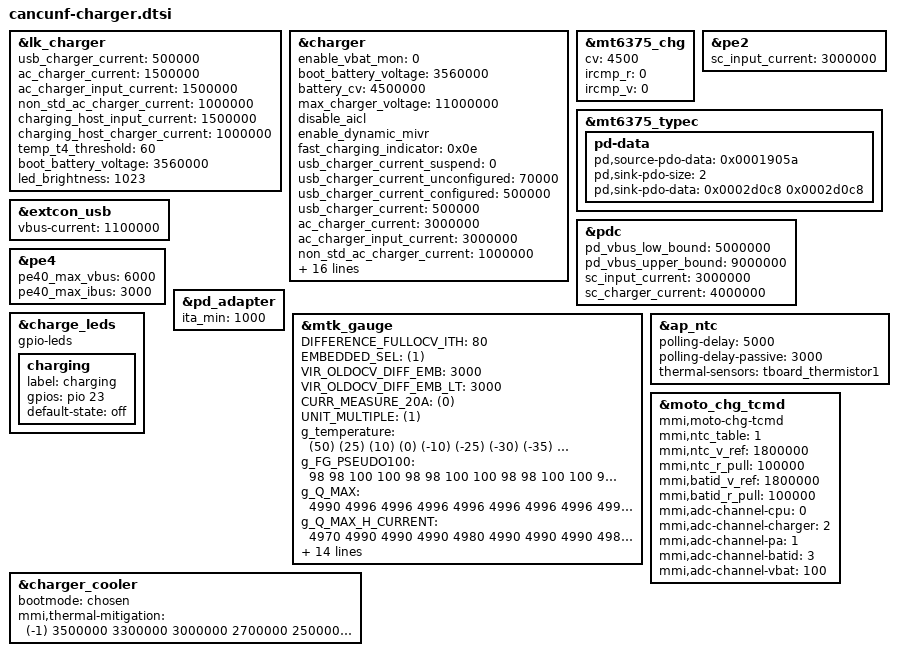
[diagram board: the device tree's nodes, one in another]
/*
 * Copyright (c) 2021 MediaTek Inc.
 *
 * This program is free software; you can redistribute it and/or modify
 * it under the terms of the GNU General Public License version 2 as
 * published by the Free Software Foundation.
 *
 * This program is distributed in the hope that it will be useful,
 * but WITHOUT ANY WARRANTY; without even the implied warranty of
 * MERCHANTABILITY or FITNESS FOR A PARTICULAR PURPOSE.  See the
 * GNU General Public License for more details.
 */

&lk_charger {
	/* charging current */
	usb_charger_current = <500000>;
	ac_charger_current = <1500000>;
	ac_charger_input_current = <1500000>;
	non_std_ac_charger_current = <1000000>;
	charging_host_input_current = <1500000>;
	charging_host_charger_current = <1000000>;

	temp_t4_threshold = <60>;

	boot_battery_voltage = <3560000>;
};

&charger {
	/* sw jeita */
	enable_vbat_mon = <0>;

	/* common */
        boot_battery_voltage = <3560000>;
	battery_cv = <4500000>;
	max_charger_voltage = <11000000>;
//	min_charger_voltage = <4600000>;

        disable_aicl;
        enable_dynamic_mivr;

	/*pdc && pe2*/
	fast_charging_indicator = <0x0e>;
	/*swchg + 1CP*/
	//charger_configuration= <3>;

	/* charging current */
	usb_charger_current_suspend = <0>;
	usb_charger_current_unconfigured = <70000>;
	usb_charger_current_configured = <500000>;
	usb_charger_current = <500000>;
	ac_charger_current = <3000000>;
	ac_charger_input_current = <3000000>;
	non_std_ac_charger_current = <1000000>;
	charging_host_charger_current = <1500000>;
	apple_1_0a_charger_current = <650000>;
	apple_2_1a_charger_current = <800000>;
	ta_ac_charger_current = <2000000>;
	typec_limit_aicr = <3000000>;

	/*mmi config*/
	mmi,iterm-ma = <243>;
	mmi,mmi-temp-zones = <0 4200 1000 0>,
			<10 4500 3000 1000>,
			<15 4500 3000 3000>,
			<45 4500 4000 4000>,
			<60 4200 4000 0>;
	mmi,mmi-ffc-zones = <0 4200 243>,
			<10 4500 243>,
			<15 4500 243>,
			<25 4530 506>,
			<35 4530 560>,
			<45 4530 965>,
			<60 4200 243>;
	mmi,enable-charging-limit;
	mmi,upper-limit-capacity = <65>;
	mmi,lower-limit-capacity = <60>;
	mmi,min-cp-therm-current-ua = <1600000>;
};

&mt6375_chg {
	cv = <4500>;
	ircmp_r = <0>;
	ircmp_v = <0>;
};
/*
&pdc {
	sc_input_current = <3000000>;
};
*/
&pe2 {
	sc_input_current = <3000000>;
};


&mt6375_typec {
	pd-data {
		/* 5V, 900ma */
		pd,source-pdo-data = <0x0001905a>;
		/* 9V, 2A */
		pd,sink-pdo-size = <2>;
                pd,sink-pdo-data = <0x0002d0c8 0x0002d0c8> ;
	};
};

&extcon_usb {
	vbus-current = <1100000>;
};


&pdc {
	pd_vbus_low_bound = <5000000>;
	pd_vbus_upper_bound = <9000000>;

	sc_input_current = <3000000>;
	sc_charger_current = <4000000>;
};



&pe4 {
	pe40_max_vbus = <6000>;
	pe40_max_ibus = <3000>;
};


&pd_adapter{
	ita_min = <1000>;
};

&mtk_gauge {

	DIFFERENCE_FULLOCV_ITH = <80>;  /*gauge cut-off current, should overtop ieoc 50ma*/
	EMBEDDED_SEL = <(1)>;  /*embedded battery,don't remove the battery for user*/
	VIR_OLDOCV_DIFF_EMB = <3000>; /*0.1mv*/
	VIR_OLDOCV_DIFF_EMB_LT = <3000>; /*0.1mv*/
        CURR_MEASURE_20A = <(0)>;
        UNIT_MULTIPLE = <(1)>;

	/* battery prop */
	g_temperature = <(50) (25) (10) (0) (-10) (-25) (-30) (-35) (-40) (-45)>;
	g_FG_PSEUDO100 = <98 98 100 100
		98 98 100 100
		98 98 100 100
		98 98 100 100
		98 98 100 100
		100 100 100 100
		100 100 100 100
		100 100 100 100
		100 100 100 100
		100 100 100 100>;

	g_Q_MAX = <4990 4996 4996 4996
		4996 4996 4996 4996
		4996 4996 4996 4996
		4996 4996 4996 4996
		4990 4996 4996 4996
		4990 4996 4996 4996
		4990 4996 4996 4996
		4990 4996 4996 4996
		4990 4996 4996 4996
		4990 4996 4996 4996>;

	g_Q_MAX_H_CURRENT = <4970 4990 4990 4990
		4980 4990 4990 4990
		4980 4990 4990 4990
		4980 4990 4990 4990
		4970 4990 4990 4990
		4970 4990 4990 4990
		4970 4990 4990 4990
		4970 4990 4990 4990
		4970 4990 4990 4990
		4970 4990 4990 4990>;

	/*vboot voltage for gauge 0%*/
	g_PMIC_MIN_VOL_row = <4>;
	g_PMIC_MIN_VOL_col = <10>;
	g_PMIC_MIN_VOL = <32000  33500  33500  33500
		32000  33500  33000  33000
		33000  33000  33000  33000
		32200  32200  32200  32200
		31360  31360  31360  31360
		31000  31000  31000  31000
		31000  31000  31000  31000
		31000  31000  31000  31000
		31000  31000  31000  31000
		31000  31000  31000  31200>;

	/*Pseudo1 hide percentage*/
	g_QMAX_SYS_VOL_row = <4>;
	g_QMAX_SYS_VOL_col = <10>;
	g_QMAX_SYS_VOL = <32500  34000  34950  34950
		32500  34000  34950  34950
		34250  34250  34250  34250
		34250  34250  34250  34250
		34250  34250  34250  34250
		34250  34250  34250  34250
		32800  32800  32800  32800
		32800  32800  32800  32800
		32800  32800  32800  32800
		32800  32800  32800  32800>;

	SHUTDOWN_1_TIME = <(30)>;
	ACTIVE_TABLE = <(5)>;
	R_FG_VALUE = <(5)>;
	NO_BAT_TEMP_COMPENSATE = <(1)>;
//	df-serialnum = "SB18D61156";
	df-serialnum = "SB18D86478";
	CAR_TUNE_VALUE = <(99)>;
	#include "bat_setting/mt6855_battery_pc50_atl_5000mah.dtsi"
	#include "bat_setting/mt6855_battery_pc50_scud_5000mah.dtsi"
//	#include "bat_setting/mt6855_battery_table_lwn_5000.dtsi"
//	#include "bat_setting/mt6855_battery_table_ff.dtsi"

};

&charge_leds {
	compatible = "gpio-leds";

	charging {
		label = "charging";
		gpios = <&pio 23 0x0>;
		default-state = "off";
	};
};

&charger_cooler {
	bootmode = <&chosen>;
	mmi,thermal-mitigation = <(-1) 3500000 3300000 3000000 2700000 2500000 2200000 2000000 1800000
				1500000 1000000 800000 500000>;
};


&ap_ntc {
	polling-delay = <5000>;
	polling-delay-passive = <3000>;
 	thermal-sensors = <&tboard_thermistor1>;
};

&moto_chg_tcmd {
	compatible = "mmi,moto-chg-tcmd";
	status = "okay";

	mmi,ntc_table = <1>;
	mmi,ntc_v_ref = <1800000>;
	mmi,ntc_r_pull = <100000>;

	mmi,batid_v_ref = <1800000>;
	mmi,batid_r_pull = <100000>;

	mmi,adc-channel-cpu = <0>;
	mmi,adc-channel-charger = <2>;
	mmi,adc-channel-pa = <1>;
	mmi,adc-channel-batid = <3>;
	mmi,adc-channel-vbat = <100>;
};

&lk_charger {
       /* LCD brightness*/
       led_brightness = <1023>;
};
